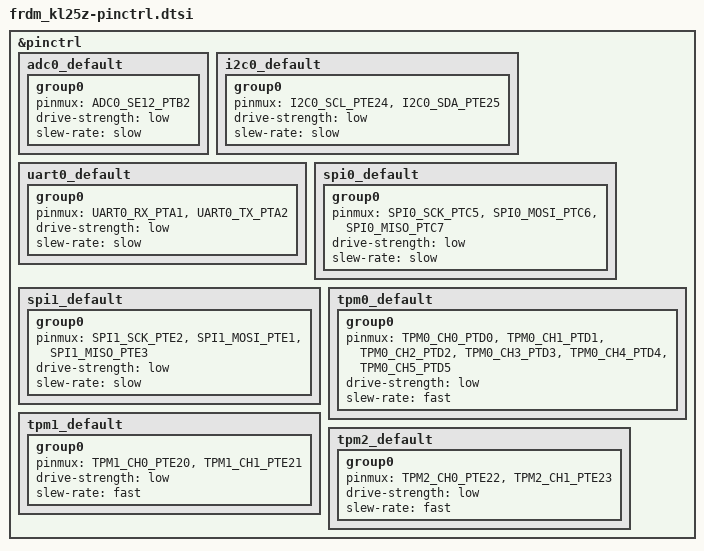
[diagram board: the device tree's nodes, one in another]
/*
 * NOTE: Autogenerated file by gen_board_pinctrl.py
 *       for MKL25Z128VLK4/signal_configuration.xml
 *
 * Copyright (c) 2022, NXP
 * SPDX-License-Identifier: Apache-2.0
 */

#include <nxp/kinetis/kl2x/pinctrl/MKL25Z128VLK4-pinctrl.h>

&pinctrl {
	adc0_default: adc0_default {
		group0 {
			pinmux = <ADC0_SE12_PTB2>;
			drive-strength = "low";
			slew-rate = "slow";
		};
	};

	i2c0_default: i2c0_default {
		group0 {
			pinmux = <I2C0_SCL_PTE24>,
				 <I2C0_SDA_PTE25>;
			drive-strength = "low";
			slew-rate = "slow";
		};
	};

	uart0_default: uart0_default {
		group0 {
			pinmux = <UART0_RX_PTA1>,
				 <UART0_TX_PTA2>;
			drive-strength = "low";
			slew-rate = "slow";
		};
	};

	spi0_default: spi0_default {
		group0 {
			pinmux = <SPI0_SCK_PTC5>,
				 <SPI0_MOSI_PTC6>,
				 <SPI0_MISO_PTC7>;
			drive-strength = "low";
			slew-rate = "slow";
		};
	};

	spi1_default: spi1_default {
		group0 {
			pinmux = <SPI1_SCK_PTE2>,
				 <SPI1_MOSI_PTE1>,
				 <SPI1_MISO_PTE3>;
			drive-strength = "low";
			slew-rate = "slow";
		};
	};

	tpm0_default: tpm0_default {
		group0 {
			pinmux = <TPM0_CH0_PTD0>,
				 <TPM0_CH1_PTD1>,
				 <TPM0_CH2_PTD2>,
				 <TPM0_CH3_PTD3>,
				 <TPM0_CH4_PTD4>,
				 <TPM0_CH5_PTD5>;
			drive-strength = "low";
			slew-rate = "fast";
		};
	};

	tpm1_default: tpm1_default {
		group0 {
			pinmux = <TPM1_CH0_PTE20>,
				 <TPM1_CH1_PTE21>;
			drive-strength = "low";
			slew-rate = "fast";
		};
	};

	tpm2_default: tpm2_default {
		group0 {
			pinmux = <TPM2_CH0_PTE22>,
				 <TPM2_CH1_PTE23>;
			drive-strength = "low";
			slew-rate = "fast";
		};
	};
};
